AUTOSAR XML (schema 00048)
package /ComponentTypes
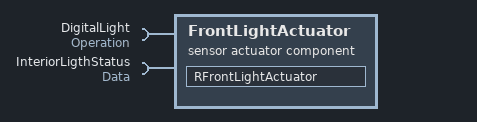
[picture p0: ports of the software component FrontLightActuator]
  sensor actuator sw component type FrontLightActuator
    require port DigitalLight: client-com-spec=DigitalServiceWrite, required-interface=Operation
    require port InteriorLigthStatus: nonqueued-receiver-com-spec=LightStatus, required-interface=Data
    behavior FrontLightActuatorInternalBehavior
      data received event ReceiveEventLightStatus: start-on-event=RFrontLightActuator, data=InteriorLigthStatus.LightStatus
      runnable RFrontLightActuator
        data-read-access:
          access ReadLightStatus: accessed-variable=InteriorLigthStatus.LightStatus
        sync call CallDigitalServiceWrite: operation=DigitalLight.DigitalServiceWrite, timeout=0.0
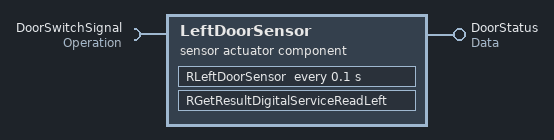
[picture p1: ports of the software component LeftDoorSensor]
  sensor actuator sw component type LeftDoorSensor
    provide port DoorStatus: nonqueued-sender-com-spec=LeftDoorStatus, provided-interface=Data
    require port DoorSwitchSignal: client-com-spec=DigitalServiceReadLeft, required-interface=Operation
    behavior LeftDoorSensorInternalBehavior
      asynchronous server call returns event GetResultEventDigitalServiceReadLeft: start-on-event=RGetResultDigitalServiceReadLeft, event-source=GetResultDigitalServiceReadLeftPoint
      timing event LeftDoorSensorTimingEvent: start-on-event=RLeftDoorSensor, period=0.1
      runnable RGetResultDigitalServiceReadLeft
        asynchronous server call result point GetResultDigitalServiceReadLeftPoint: asynchronous-server-call-point=CallDigitalServiceReadLeft
        data-write-access:
          access WriteLeftDoorStatus: accessed-variable=DoorStatus.LeftDoorStatus
      runnable RLeftDoorSensor
        async call CallDigitalServiceReadLeft: operation=DoorSwitchSignal.DigitalServiceReadLeft, timeout=0.0
  composition sw component type LeftDoorSensorLightManager: assembly-sw-connector{provider=LeftDoorSensor.DoorStatus, requester=LightManager.LeftDoorStatus}
    component LeftDoorSensor: type=LeftDoorSensor
    component LightManager: type=LightManager
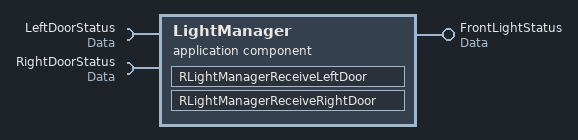
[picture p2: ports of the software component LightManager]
  application sw component type LightManager
    provide port FrontLightStatus: nonqueued-sender-com-spec=LightStatus, provided-interface=Data
    require port LeftDoorStatus: nonqueued-receiver-com-spec=LeftDoorStatus, required-interface=Data
    require port RightDoorStatus: nonqueued-receiver-com-spec=RightDoorStatus, required-interface=Data
    behavior LightManagerInternalBehavior
      data received event ReceiveEventLeftDoorStatus: start-on-event=RLightManagerReceiveLeftDoor, data=LeftDoorStatus.LeftDoorStatus
      data received event ReceiveEventRightDoorStatus: start-on-event=RLightManagerReceiveRightDoor, data=RightDoorStatus.RightDoorStatus
      runnable RLightManagerReceiveLeftDoor: variable-access=accessed-variable=LeftDoorStatus.LeftDoorStatus, variable-access=accessed-variable=FrontLightStatus.LightStatus
      runnable RLightManagerReceiveRightDoor: variable-access=accessed-variable=RightDoorStatus.RightDoorStatus, variable-access=accessed-variable=FrontLightStatus.LightStatus
  composition sw component type LightManagerFrontLightActuator: assembly-sw-connector{provider=LightManager.FrontLightStatus, requester=FrontLightActuator.InteriorLigthStatus}
    component FrontLightActuator: type=FrontLightActuator
    component LightManager: type=LightManager
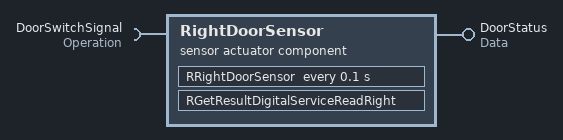
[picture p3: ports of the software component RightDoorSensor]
  sensor actuator sw component type RightDoorSensor
    provide port DoorStatus: nonqueued-sender-com-spec=RightDoorStatus, provided-interface=Data
    require port DoorSwitchSignal: client-com-spec=DigitalServiceReadRight, required-interface=Operation
    behavior RightDoorSensorInternalBehavior
      asynchronous server call returns event GetResultEventDigitalServiceReadRight: start-on-event=RGetResultDigitalServiceReadRight, event-source=GetResultDigitalServiceReadRightPoint
      timing event RightDoorSensorTimingEvent: start-on-event=RRightDoorSensor, period=0.1
      runnable RGetResultDigitalServiceReadRight
        asynchronous server call result point GetResultDigitalServiceReadRightPoint: asynchronous-server-call-point=CallDigitalServiceReadRight
        data-write-access:
          access WriteRightDoorStatus: accessed-variable=DoorStatus.RightDoorStatus
      runnable RRightDoorSensor
        async call CallDigitalServiceReadRight: operation=DoorSwitchSignal.DigitalServiceReadRight, timeout=0.0
  composition sw component type RightDoorSensorLightManager: assembly-sw-connector{provider=RightDoorSensor.DoorStatus, requester=LightManager.RightDoorStatus}
    component LightManager: type=LightManager
    component RightDoorSensor: type=RightDoorSensor
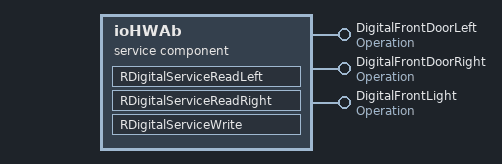
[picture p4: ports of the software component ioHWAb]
  service sw component type ioHWAb
    provide port DigitalFrontDoorLeft: server-com-spec{operation=DigitalServiceReadLeft, queue-length=1}, provided-interface=Operation
    provide port DigitalFrontDoorRight: server-com-spec{operation=DigitalServiceReadRight, queue-length=1}, provided-interface=Operation
    provide port DigitalFrontLight: server-com-spec{operation=DigitalServiceWrite, queue-length=1}, provided-interface=Operation
    behavior ioHWAbInternalBehavior
      operation invoked event EventDigitalServiceReadLeft: start-on-event=RDigitalServiceReadLeft, operation=DigitalFrontDoorLeft.DigitalServiceReadLeft
      operation invoked event EventDigitalServiceReadRight: start-on-event=RDigitalServiceReadRight, operation=DigitalFrontDoorRight.DigitalServiceReadRight
      operation invoked event EventDigitalServiceWrite: start-on-event=RDigitalServiceWrite, operation=DigitalFrontLight.DigitalServiceWrite
      runnable RDigitalServiceReadLeft
      runnable RDigitalServiceReadRight
      runnable RDigitalServiceWrite
  composition sw component type ioHWAbFrontLightActuator: assembly-sw-connector{provider=ioHWAb.DigitalFrontLight, requester=FrontLightActuator.DigitalLight}
    component FrontLightActuator: type=FrontLightActuator
    component ioHWAb: type=ioHWAb
  composition sw component type ioHWAbLeftDoorSensor: assembly-sw-connector{provider=ioHWAb.DigitalFrontDoorLeft, requester=LeftDoorSensor.DoorSwitchSignal}
    component LeftDoorSensor: type=LeftDoorSensor
    component ioHWAb: type=ioHWAb
  composition sw component type ioHWAbRightDoorSensor: assembly-sw-connector{provider=ioHWAb.DigitalFrontDoorRight, requester=RightDoorSensor.DoorSwitchSignal}
    component RightDoorSensor: type=RightDoorSensor
    component ioHWAb: type=ioHWAb
package /PortInterfaces
  sender receiver interface Data
    data LeftDoorStatus
    data LightStatus
    data RightDoorStatus
  client server interface Operation
    operation DigitalServiceReadLeft
    operation DigitalServiceReadRight
    operation DigitalServiceWrite
